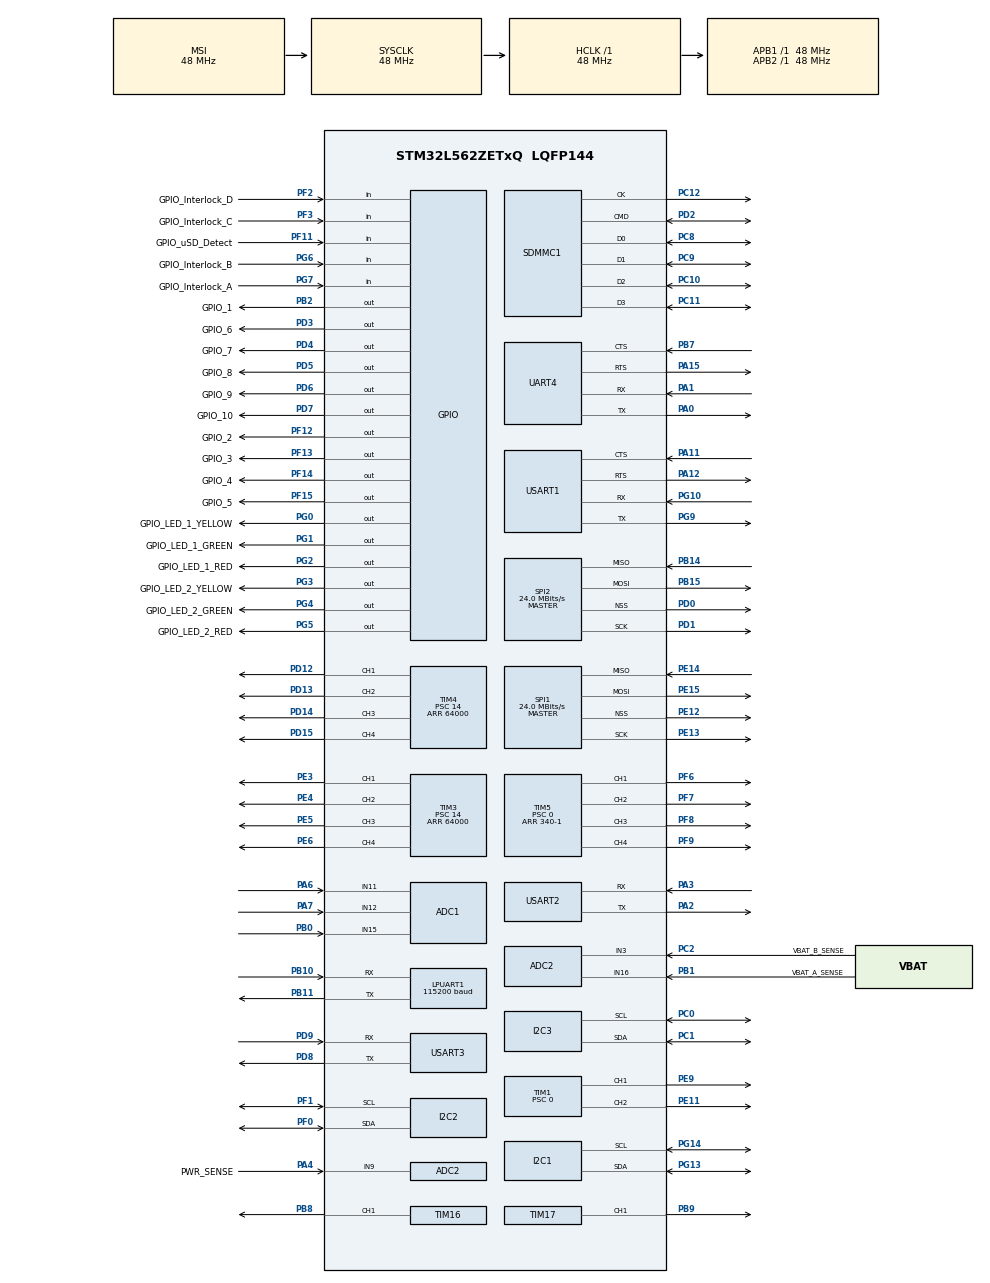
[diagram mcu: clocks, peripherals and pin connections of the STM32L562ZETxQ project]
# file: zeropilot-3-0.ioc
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ADC1.Channel-0\#ChannelRegularConversion=ADC_CHANNEL_11
ADC1.Channel-3\#ChannelRegularConversion=ADC_CHANNEL_12
ADC1.Channel-4\#ChannelRegularConversion=ADC_CHANNEL_15
ADC1.ClockPrescaler=ADC_CLOCK_ASYNC_DIV256
ADC1.ContinuousConvMode=ENABLE
ADC1.DMAContinuousRequests=ENABLE
ADC1.NbrOfConversion=3
ADC1.NbrOfConversionFlag=1
ADC1.OffsetNumber-3\#ChannelRegularConversion=ADC_OFFSET_NONE
ADC1.OffsetNumber-4\#ChannelRegularConversion=ADC_OFFSET_NONE
ADC1.Rank-3\#ChannelRegularConversion=2
ADC1.Rank-4\#ChannelRegularConversion=3
ADC1.SamplingTime-0\#ChannelRegularConversion=ADC_SAMPLETIME_640CYCLES_5
ADC1.SamplingTime-3\#ChannelRegularConversion=ADC_SAMPLETIME_640CYCLES_5
ADC1.SamplingTime-4\#ChannelRegularConversion=ADC_SAMPLETIME_640CYCLES_5
ADC1.master=1
ADC2.AutoInjectedConv-ADC_Injected_ConversionMode=ENABLE
ADC2.Channel-0\#ChannelRegularConversion=ADC_CHANNEL_3
ADC2.Channel-3\#ChannelRegularConversion=ADC_CHANNEL_9
ADC2.Channel-4\#ChannelRegularConversion=ADC_CHANNEL_16
ADC2.ClockPrescaler=ADC_CLOCK_ASYNC_DIV256
ADC2.ContinuousConvMode=ENABLE
ADC2.DMAContinuousRequests=ENABLE
ADC2.NbrOfConversion=3
ADC2.NbrOfConversionFlag=1
ADC2.OffsetNumber-3\#ChannelRegularConversion=ADC_OFFSET_NONE
ADC2.OffsetNumber-4\#ChannelRegularConversion=ADC_OFFSET_NONE
ADC2.Rank-3\#ChannelRegularConversion=2
ADC2.Rank-4\#ChannelRegularConversion=3
ADC2.SamplingTime-0\#ChannelRegularConversion=ADC_SAMPLETIME_640CYCLES_5
ADC2.SamplingTime-3\#ChannelRegularConversion=ADC_SAMPLETIME_640CYCLES_5
ADC2.SamplingTime-4\#ChannelRegularConversion=ADC_SAMPLETIME_640CYCLES_5
Dma.ADC1.8.Channel_PRIV_NPRIV=DMA_CHANNEL_NPRIV_DISABLE
Dma.ADC1.8.Direction=DMA_PERIPH_TO_MEMORY
Dma.ADC1.8.EventEnable=DISABLE
Dma.ADC1.8.Instance=DMA2_Channel1
Dma.ADC1.8.MemDataAlignment=DMA_MDATAALIGN_WORD
Dma.ADC1.8.MemInc=DMA_MINC_ENABLE
Dma.ADC1.8.Mode=DMA_CIRCULAR
Dma.ADC1.8.PeriphDataAlignment=DMA_PDATAALIGN_HALFWORD
Dma.ADC1.8.PeriphInc=DMA_PINC_DISABLE
Dma.ADC1.8.Polarity=HAL_DMAMUX_REQ_GEN_RISING
Dma.ADC1.8.Priority=DMA_PRIORITY_LOW
Dma.ADC1.8.RequestNumber=1
Dma.ADC1.8.SignalID=NONE
Dma.ADC1.8.SyncEnable=DISABLE
Dma.ADC1.8.SyncPolarity=HAL_DMAMUX_SYNC_NO_EVENT
Dma.ADC1.8.SyncRequestNumber=1
Dma.ADC1.8.SyncSignalID=NONE
Dma.ADC2.9.Channel_PRIV_NPRIV=DMA_CHANNEL_NPRIV_DISABLE
Dma.ADC2.9.Direction=DMA_PERIPH_TO_MEMORY
Dma.ADC2.9.EventEnable=DISABLE
Dma.ADC2.9.Instance=DMA2_Channel2
Dma.ADC2.9.MemDataAlignment=DMA_MDATAALIGN_WORD
Dma.ADC2.9.MemInc=DMA_MINC_ENABLE
Dma.ADC2.9.Mode=DMA_CIRCULAR
Dma.ADC2.9.PeriphDataAlignment=DMA_PDATAALIGN_HALFWORD
Dma.ADC2.9.PeriphInc=DMA_PINC_DISABLE
Dma.ADC2.9.Polarity=HAL_DMAMUX_REQ_GEN_RISING
Dma.ADC2.9.Priority=DMA_PRIORITY_LOW
Dma.ADC2.9.RequestNumber=1
Dma.ADC2.9.SignalID=NONE
Dma.ADC2.9.SyncEnable=DISABLE
Dma.ADC2.9.SyncPolarity=HAL_DMAMUX_SYNC_NO_EVENT
Dma.ADC2.9.SyncRequestNumber=1
Dma.ADC2.9.SyncSignalID=NONE
Dma.Request0=TIM16_CH1
Dma.Request1=TIM17_CH1
Dma.Request2=TIM1_CH1
Dma.Request3=TIM1_CH2
Dma.Request4=TIM5_CH1
Dma.Request5=TIM5_CH2
Dma.Request6=TIM5_CH3
Dma.Request7=TIM5_CH4
Dma.Request8=ADC1
Dma.Request9=ADC2
Dma.TIM16_CH1.0.Channel_PRIV_NPRIV=DMA_CHANNEL_NPRIV_DISABLE
Dma.TIM16_CH1.0.Direction=DMA_MEMORY_TO_PERIPH
Dma.TIM16_CH1.0.EventEnable=DISABLE
Dma.TIM16_CH1.0.Instance=DMA1_Channel1
Dma.TIM16_CH1.0.MemDataAlignment=DMA_MDATAALIGN_WORD
Dma.TIM16_CH1.0.MemInc=DMA_MINC_ENABLE
Dma.TIM16_CH1.0.Mode=DMA_CIRCULAR
Dma.TIM16_CH1.0.PeriphDataAlignment=DMA_PDATAALIGN_WORD
Dma.TIM16_CH1.0.PeriphInc=DMA_PINC_DISABLE
Dma.TIM16_CH1.0.Polarity=HAL_DMAMUX_REQ_GEN_RISING
Dma.TIM16_CH1.0.Priority=DMA_PRIORITY_HIGH
Dma.TIM16_CH1.0.RequestNumber=1
Dma.TIM16_CH1.0.SignalID=NONE
Dma.TIM16_CH1.0.SyncEnable=DISABLE
Dma.TIM16_CH1.0.SyncPolarity=HAL_DMAMUX_SYNC_NO_EVENT
Dma.TIM16_CH1.0.SyncRequestNumber=1
Dma.TIM16_CH1.0.SyncSignalID=NONE
Dma.TIM17_CH1.1.Channel_PRIV_NPRIV=DMA_CHANNEL_NPRIV_DISABLE
Dma.TIM17_CH1.1.Direction=DMA_MEMORY_TO_PERIPH
Dma.TIM17_CH1.1.EventEnable=DISABLE
Dma.TIM17_CH1.1.Instance=DMA1_Channel2
Dma.TIM17_CH1.1.MemDataAlignment=DMA_MDATAALIGN_WORD
Dma.TIM17_CH1.1.MemInc=DMA_MINC_ENABLE
Dma.TIM17_CH1.1.Mode=DMA_CIRCULAR
Dma.TIM17_CH1.1.PeriphDataAlignment=DMA_PDATAALIGN_WORD
Dma.TIM17_CH1.1.PeriphInc=DMA_PINC_DISABLE
Dma.TIM17_CH1.1.Polarity=HAL_DMAMUX_REQ_GEN_RISING
Dma.TIM17_CH1.1.Priority=DMA_PRIORITY_HIGH
Dma.TIM17_CH1.1.RequestNumber=1
Dma.TIM17_CH1.1.SignalID=NONE
Dma.TIM17_CH1.1.SyncEnable=DISABLE
Dma.TIM17_CH1.1.SyncPolarity=HAL_DMAMUX_SYNC_NO_EVENT
Dma.TIM17_CH1.1.SyncRequestNumber=1
Dma.TIM17_CH1.1.SyncSignalID=NONE
Dma.TIM1_CH1.2.Channel_PRIV_NPRIV=DMA_CHANNEL_NPRIV_DISABLE
Dma.TIM1_CH1.2.Direction=DMA_MEMORY_TO_PERIPH
Dma.TIM1_CH1.2.EventEnable=DISABLE
Dma.TIM1_CH1.2.Instance=DMA1_Channel3
Dma.TIM1_CH1.2.MemDataAlignment=DMA_MDATAALIGN_WORD
Dma.TIM1_CH1.2.MemInc=DMA_MINC_ENABLE
Dma.TIM1_CH1.2.Mode=DMA_CIRCULAR
Dma.TIM1_CH1.2.PeriphDataAlignment=DMA_PDATAALIGN_WORD
Dma.TIM1_CH1.2.PeriphInc=DMA_PINC_DISABLE
Dma.TIM1_CH1.2.Polarity=HAL_DMAMUX_REQ_GEN_RISING
Dma.TIM1_CH1.2.Priority=DMA_PRIORITY_HIGH
Dma.TIM1_CH1.2.RequestNumber=1
Dma.TIM1_CH1.2.SignalID=NONE
Dma.TIM1_CH1.2.SyncEnable=DISABLE
Dma.TIM1_CH1.2.SyncPolarity=HAL_DMAMUX_SYNC_NO_EVENT
Dma.TIM1_CH1.2.SyncRequestNumber=1
Dma.TIM1_CH1.2.SyncSignalID=NONE
Dma.TIM1_CH2.3.Channel_PRIV_NPRIV=DMA_CHANNEL_NPRIV_DISABLE
Dma.TIM1_CH2.3.Direction=DMA_MEMORY_TO_PERIPH
Dma.TIM1_CH2.3.EventEnable=DISABLE
Dma.TIM1_CH2.3.Instance=DMA1_Channel4
Dma.TIM1_CH2.3.MemDataAlignment=DMA_MDATAALIGN_WORD
Dma.TIM1_CH2.3.MemInc=DMA_MINC_ENABLE
Dma.TIM1_CH2.3.Mode=DMA_CIRCULAR
Dma.TIM1_CH2.3.PeriphDataAlignment=DMA_PDATAALIGN_WORD
Dma.TIM1_CH2.3.PeriphInc=DMA_PINC_DISABLE
Dma.TIM1_CH2.3.Polarity=HAL_DMAMUX_REQ_GEN_RISING
Dma.TIM1_CH2.3.Priority=DMA_PRIORITY_HIGH
Dma.TIM1_CH2.3.RequestNumber=1
Dma.TIM1_CH2.3.SignalID=NONE
Dma.TIM1_CH2.3.SyncEnable=DISABLE
Dma.TIM1_CH2.3.SyncPolarity=HAL_DMAMUX_SYNC_NO_EVENT
Dma.TIM1_CH2.3.SyncRequestNumber=1
Dma.TIM1_CH2.3.SyncSignalID=NONE
Dma.TIM5_CH1.4.Channel_PRIV_NPRIV=DMA_CHANNEL_NPRIV_DISABLE
Dma.TIM5_CH1.4.Direction=DMA_MEMORY_TO_PERIPH
Dma.TIM5_CH1.4.EventEnable=DISABLE
Dma.TIM5_CH1.4.Instance=DMA1_Channel5
Dma.TIM5_CH1.4.MemDataAlignment=DMA_MDATAALIGN_WORD
Dma.TIM5_CH1.4.MemInc=DMA_MINC_ENABLE
Dma.TIM5_CH1.4.Mode=DMA_CIRCULAR
Dma.TIM5_CH1.4.PeriphDataAlignment=DMA_PDATAALIGN_WORD
Dma.TIM5_CH1.4.PeriphInc=DMA_PINC_DISABLE
Dma.TIM5_CH1.4.Polarity=HAL_DMAMUX_REQ_GEN_RISING
Dma.TIM5_CH1.4.Priority=DMA_PRIORITY_HIGH
Dma.TIM5_CH1.4.RequestNumber=1
Dma.TIM5_CH1.4.SignalID=NONE
Dma.TIM5_CH1.4.SyncEnable=DISABLE
Dma.TIM5_CH1.4.SyncPolarity=HAL_DMAMUX_SYNC_NO_EVENT
Dma.TIM5_CH1.4.SyncRequestNumber=1
Dma.TIM5_CH1.4.SyncSignalID=NONE
Dma.TIM5_CH2.5.Channel_PRIV_NPRIV=DMA_CHANNEL_NPRIV_DISABLE
Dma.TIM5_CH2.5.Direction=DMA_MEMORY_TO_PERIPH
Dma.TIM5_CH2.5.EventEnable=DISABLE
Dma.TIM5_CH2.5.Instance=DMA1_Channel6
Dma.TIM5_CH2.5.MemDataAlignment=DMA_MDATAALIGN_WORD
Dma.TIM5_CH2.5.MemInc=DMA_MINC_ENABLE
Dma.TIM5_CH2.5.Mode=DMA_CIRCULAR
Dma.TIM5_CH2.5.PeriphDataAlignment=DMA_PDATAALIGN_WORD
Dma.TIM5_CH2.5.PeriphInc=DMA_PINC_DISABLE
Dma.TIM5_CH2.5.Polarity=HAL_DMAMUX_REQ_GEN_RISING
Dma.TIM5_CH2.5.Priority=DMA_PRIORITY_HIGH
Dma.TIM5_CH2.5.RequestNumber=1
Dma.TIM5_CH2.5.SignalID=NONE
Dma.TIM5_CH2.5.SyncEnable=DISABLE
Dma.TIM5_CH2.5.SyncPolarity=HAL_DMAMUX_SYNC_NO_EVENT
Dma.TIM5_CH2.5.SyncRequestNumber=1
Dma.TIM5_CH2.5.SyncSignalID=NONE
Dma.TIM5_CH3.6.Channel_PRIV_NPRIV=DMA_CHANNEL_NPRIV_DISABLE
Dma.TIM5_CH3.6.Direction=DMA_MEMORY_TO_PERIPH
Dma.TIM5_CH3.6.EventEnable=DISABLE
Dma.TIM5_CH3.6.Instance=DMA1_Channel7
Dma.TIM5_CH3.6.MemDataAlignment=DMA_MDATAALIGN_WORD
Dma.TIM5_CH3.6.MemInc=DMA_MINC_ENABLE
Dma.TIM5_CH3.6.Mode=DMA_CIRCULAR
Dma.TIM5_CH3.6.PeriphDataAlignment=DMA_PDATAALIGN_WORD
Dma.TIM5_CH3.6.PeriphInc=DMA_PINC_DISABLE
Dma.TIM5_CH3.6.Polarity=HAL_DMAMUX_REQ_GEN_RISING
Dma.TIM5_CH3.6.Priority=DMA_PRIORITY_HIGH
Dma.TIM5_CH3.6.RequestNumber=1
Dma.TIM5_CH3.6.SignalID=NONE
Dma.TIM5_CH3.6.SyncEnable=DISABLE
Dma.TIM5_CH3.6.SyncPolarity=HAL_DMAMUX_SYNC_NO_EVENT
Dma.TIM5_CH3.6.SyncRequestNumber=1
Dma.TIM5_CH3.6.SyncSignalID=NONE
Dma.TIM5_CH4.7.Channel_PRIV_NPRIV=DMA_CHANNEL_NPRIV_DISABLE
Dma.TIM5_CH4.7.Direction=DMA_MEMORY_TO_PERIPH
Dma.TIM5_CH4.7.EventEnable=DISABLE
Dma.TIM5_CH4.7.Instance=DMA1_Channel8
Dma.TIM5_CH4.7.MemDataAlignment=DMA_MDATAALIGN_WORD
Dma.TIM5_CH4.7.MemInc=DMA_MINC_ENABLE
Dma.TIM5_CH4.7.Mode=DMA_CIRCULAR
Dma.TIM5_CH4.7.PeriphDataAlignment=DMA_PDATAALIGN_WORD
Dma.TIM5_CH4.7.PeriphInc=DMA_PINC_DISABLE
Dma.TIM5_CH4.7.Polarity=HAL_DMAMUX_REQ_GEN_RISING
Dma.TIM5_CH4.7.Priority=DMA_PRIORITY_HIGH
Dma.TIM5_CH4.7.RequestNumber=1
Dma.TIM5_CH4.7.SignalID=NONE
Dma.TIM5_CH4.7.SyncEnable=DISABLE
Dma.TIM5_CH4.7.SyncPolarity=HAL_DMAMUX_SYNC_NO_EVENT
Dma.TIM5_CH4.7.SyncRequestNumber=1
Dma.TIM5_CH4.7.SyncSignalID=NONE
FREERTOS.Tasks01=defaultTask,24,128,StartDefaultTask,Default,NULL,Dynamic,NULL,NULL
I2C1.Timing=0x20303E5D
I2C2.Timing=0x20303E5D
I2C3.Timing=0x20303E5D
LPUART1.BaudRate=115200
Mcu.Family=STM32L5
Mcu.Name=STM32L562ZETxQ
Mcu.Package=LQFP144
NVIC.DMA1_Channel1_IRQn=true\:5\:0\:false\:false\:true\:true\:false\:true\:true
NVIC.DMA1_Channel2_IRQn=true\:5\:0\:false\:false\:true\:true\:false\:true\:true
NVIC.DMA1_Channel3_IRQn=true\:5\:0\:false\:false\:true\:true\:false\:true\:true
NVIC.DMA1_Channel4_IRQn=true\:5\:0\:false\:false\:true\:true\:false\:true\:true
NVIC.DMA1_Channel5_IRQn=true\:5\:0\:false\:false\:true\:true\:false\:true\:true
NVIC.DMA1_Channel6_IRQn=true\:5\:0\:false\:false\:true\:true\:false\:true\:true
NVIC.DMA1_Channel7_IRQn=true\:5\:0\:false\:false\:true\:true\:false\:true\:true
NVIC.DMA1_Channel8_IRQn=true\:5\:0\:false\:false\:true\:true\:false\:true\:true
NVIC.DMA2_Channel1_IRQn=true\:5\:0\:false\:false\:true\:true\:false\:true\:true
NVIC.DMA2_Channel2_IRQn=true\:5\:0\:false\:false\:true\:true\:false\:true\:true
NVIC.PriorityGroup=NVIC_PRIORITYGROUP_3
NVIC.TIM6_IRQn=true\:7\:0\:false\:false\:true\:false\:false\:true\:true
NVIC.TimeBase=TIM6_IRQn
NVIC.TimeBaseIP=TIM6
PA0.Mode=Asynchronous
PA0.Signal=UART4_TX
PA1.Mode=Asynchronous
PA1.Signal=UART4_RX
PA11.Mode=CTS_RTS
PA11.Signal=USART1_CTS
PA12.Mode=CTS_RTS
PA12.Signal=USART1_RTS
PA15\ (JTDI).Mode=CTS_RTS
PA15\ (JTDI).Signal=UART4_RTS
PA2.Mode=Asynchronous
PA2.Signal=USART2_TX
PA3.Mode=Asynchronous
PA3.Signal=USART2_RX
PA4.GPIO_Label=PWR_SENSE
PA4.GPIO_Mode=GPIO_MODE_ANALOG
PA4.GPIO_PuPd=GPIO_NOPULL
PA4.Signal=ADCx_IN9
PA6.Signal=ADCx_IN11
PA7.Signal=ADCx_IN12
PB0.Signal=ADCx_IN15
PB1.GPIO_Label=VBAT_A_SENSE
PB1.GPIO_Mode=GPIO_MODE_ANALOG
PB1.GPIO_PuPd=GPIO_NOPULL
PB1.Signal=ADCx_IN16
PB10.Mode=Asynchronous
PB10.Signal=LPUART1_RX
PB11.Mode=Asynchronous
PB11.Signal=LPUART1_TX
PB14.Mode=Full_Duplex_Master
PB14.PinAttribute=Free
PB14.Signal=SPI2_MISO
PB15.Mode=Full_Duplex_Master
PB15.PinAttribute=Free
PB15.Signal=SPI2_MOSI
PB2.GPIO_Label=GPIO_1
PB2.Signal=GPIO_Output
PB7.Mode=CTS_RTS
PB7.Signal=UART4_CTS
PB8.Signal=S_TIM16_CH1
PB9.Signal=S_TIM17_CH1
PC0.Mode=I2C
PC0.Signal=I2C3_SCL
PC1.Mode=I2C
PC1.Signal=I2C3_SDA
PC10.Mode=SD_4_bits_Wide_bus
PC10.Signal=SDMMC1_D2
PC11.Mode=SD_4_bits_Wide_bus
PC11.Signal=SDMMC1_D3
PC12.Mode=SD_4_bits_Wide_bus
PC12.Signal=SDMMC1_CK
PC2.GPIO_Label=VBAT_B_SENSE
PC2.GPIO_Mode=GPIO_MODE_ANALOG
PC2.GPIO_PuPd=GPIO_NOPULL
PC2.Signal=ADCx_IN3
PC8.Mode=SD_4_bits_Wide_bus
PC8.Signal=SDMMC1_D0
PC9.Mode=SD_4_bits_Wide_bus
PC9.Signal=SDMMC1_D1
PD0.Mode=NSS_Signal_Hard_Output
PD0.PinAttribute=Free
PD0.Signal=SPI2_NSS
PD1.Mode=Full_Duplex_Master
PD1.PinAttribute=Free
PD1.Signal=SPI2_SCK
PD12.Signal=S_TIM4_CH1
PD13.Signal=S_TIM4_CH2
PD14.Signal=S_TIM4_CH3
PD15.PinAttribute=Free
PD15.Signal=S_TIM4_CH4
PD2.Mode=SD_4_bits_Wide_bus
PD2.Signal=SDMMC1_CMD
PD3.GPIO_Label=GPIO_6
PD3.Signal=GPIO_Output
PD4.GPIO_Label=GPIO_7
PD4.Signal=GPIO_Output
PD5.GPIO_Label=GPIO_8
PD5.Signal=GPIO_Output
PD6.GPIO_Label=GPIO_9
PD6.Signal=GPIO_Output
PD7.GPIO_Label=GPIO_10
PD7.Signal=GPIO_Output
PD8.Mode=Asynchronous
PD8.PinAttribute=Free
PD8.Signal=USART3_TX
PD9.Mode=Asynchronous
PD9.PinAttribute=Free
PD9.Signal=USART3_RX
PE11.PinAttribute=Free
PE11.Signal=S_TIM1_CH2
PE12.Mode=NSS_Signal_Hard_Output
PE12.Signal=SPI1_NSS
PE13.Mode=Full_Duplex_Master
PE13.Signal=SPI1_SCK
PE14.Mode=Full_Duplex_Master
PE14.Signal=SPI1_MISO
PE15.Mode=Full_Duplex_Master
PE15.Signal=SPI1_MOSI
PE3.Signal=S_TIM3_CH1
PE4.Signal=S_TIM3_CH2
PE5.Signal=S_TIM3_CH3
PE6.Signal=S_TIM3_CH4
PE9.Signal=S_TIM1_CH1
PF0.Mode=I2C
PF0.Signal=I2C2_SDA
PF1.Mode=I2C
PF1.Signal=I2C2_SCL
PF11.GPIO_Label=GPIO_uSD_Detect
PF11.Signal=GPIO_Input
PF12.GPIO_Label=GPIO_2
PF12.Signal=GPIO_Output
PF13.GPIO_Label=GPIO_3
PF13.Signal=GPIO_Output
PF14.GPIO_Label=GPIO_4
PF14.Signal=GPIO_Output
PF15.GPIO_Label=GPIO_5
PF15.Signal=GPIO_Output
PF2.GPIO_Label=GPIO_Interlock_D
PF2.Signal=GPIO_Input
PF3.GPIO_Label=GPIO_Interlock_C
PF3.Signal=GPIO_Input
PF6.Signal=S_TIM5_CH1
PF7.Signal=S_TIM5_CH2
PF8.Signal=S_TIM5_CH3
PF9.Signal=S_TIM5_CH4
PG0.GPIO_Label=GPIO_LED_1_YELLOW
PG0.GPIO_ModeDefaultOutputPP=GPIO_MODE_OUTPUT_PP
PG0.GPIO_PuPd=GPIO_NOPULL
PG0.PinState=GPIO_PIN_SET
PG0.Signal=GPIO_Output
PG1.GPIO_Label=GPIO_LED_1_GREEN
PG1.PinState=GPIO_PIN_SET
PG1.Signal=GPIO_Output
PG10.Mode=Asynchronous
PG10.Signal=USART1_RX
PG13.Mode=I2C
PG13.Signal=I2C1_SDA
PG14.Mode=I2C
PG14.Signal=I2C1_SCL
PG2.GPIO_Label=GPIO_LED_1_RED
PG2.PinAttribute=Free
PG2.PinState=GPIO_PIN_SET
PG2.Signal=GPIO_Output
PG3.GPIO_Label=GPIO_LED_2_YELLOW
PG3.PinAttribute=Free
PG3.PinState=GPIO_PIN_SET
PG3.Signal=GPIO_Output
PG4.GPIO_Label=GPIO_LED_2_GREEN
PG4.PinAttribute=Free
PG4.PinState=GPIO_PIN_SET
PG4.Signal=GPIO_Output
PG5.GPIO_Label=GPIO_LED_2_RED
PG5.PinState=GPIO_PIN_SET
PG5.Signal=GPIO_Output
PG6.GPIO_Label=GPIO_Interlock_B
PG6.Signal=GPIO_Input
PG7.GPIO_Label=GPIO_Interlock_A
PG7.Signal=GPIO_Input
PG9.Mode=Asynchronous
PG9.Signal=USART1_TX
ProjectManager.HeapSize=0x400
ProjectManager.StackSize=0x800
ProjectManager.TargetToolchain=STM32CubeIDE
RCC.ADCFreq_Value=8000000
RCC.AHBFreq_Value=48000000
RCC.APB1Freq_Value=48000000
RCC.APB1TimFreq_Value=48000000
RCC.APB2Freq_Value=48000000
RCC.APB2TimFreq_Value=48000000
RCC.CortexFreq_Value=48000000
RCC.HCLKFreq_Value=48000000
RCC.HSE_VALUE=8000000
RCC.HSI48_VALUE=48000000
RCC.HSI_VALUE=16000000
RCC.LSE_VALUE=32768
RCC.MSIClockRange=RCC_MSIRANGE_11
RCC.MSI_VALUE=48000000
RCC.PLLN=17
RCC.PLLP=RCC_PLLP_DIV17
RCC.PLLSAI1M=2
RCC.PLLSAI1R=RCC_PLLR_DIV8
RCC.PLLSAI1Source=RCC_PLLSAI1SOURCE_HSI
RCC.PLLSAI2Source=RCC_PLLSAI2SOURCE_HSI
RCC.PLLSourceVirtual=RCC_PLLSOURCE_HSI
RCC.SYSCLKFreq_VALUE=48000000
RCC.USBFreq_Value=32000000
RCC.VCOOutputFreq_Value=272000000
SDMMC1.ClockDiv=0
SDMMC1.HardwareFlowControl=SDMMC_HARDWARE_FLOW_CONTROL_DISABLE
SH.ADCx_IN11.0=ADC1_IN11,IN11-Single-Ended
SH.ADCx_IN12.0=ADC1_IN12,IN12-Single-Ended
SH.ADCx_IN15.0=ADC1_IN15,IN15-Single-Ended
SH.ADCx_IN16.0=ADC2_IN16,IN16-Single-Ended
SH.ADCx_IN3.0=ADC2_IN3,IN3-Single-Ended
SH.ADCx_IN9.0=ADC2_IN9,IN9-Single-Ended
SH.S_TIM16_CH1.0=TIM16_CH1,PWM Generation1 CH1
SH.S_TIM17_CH1.0=TIM17_CH1,PWM Generation1 CH1
SH.S_TIM1_CH1.0=TIM1_CH1,PWM Generation1 CH1
SH.S_TIM1_CH2.0=TIM1_CH2,PWM Generation2 CH2
SH.S_TIM3_CH1.0=TIM3_CH1,PWM Generation1 CH1
SH.S_TIM3_CH2.0=TIM3_CH2,PWM Generation2 CH2
SH.S_TIM3_CH3.0=TIM3_CH3,PWM Generation3 CH3
SH.S_TIM3_CH4.0=TIM3_CH4,PWM Generation4 CH4
SH.S_TIM4_CH1.0=TIM4_CH1,PWM Generation1 CH1
SH.S_TIM4_CH2.0=TIM4_CH2,PWM Generation2 CH2
SH.S_TIM4_CH3.0=TIM4_CH3,PWM Generation3 CH3
SH.S_TIM4_CH4.0=TIM4_CH4,PWM Generation4 CH4
SH.S_TIM5_CH1.0=TIM5_CH1,PWM Generation1 CH1
SH.S_TIM5_CH2.0=TIM5_CH2,PWM Generation2 CH2
SH.S_TIM5_CH3.0=TIM5_CH3,PWM Generation3 CH3
SH.S_TIM5_CH4.0=TIM5_CH4,PWM Generation4 CH4
SPI1.BaudRatePrescaler=SPI_BAUDRATEPRESCALER_2
SPI1.CalculateBaudRate=24.0 MBits/s
SPI1.Direction=SPI_DIRECTION_2LINES
SPI1.Mode=SPI_MODE_MASTER
SPI1.VirtualNSS=VM_NSSHARD
SPI1.VirtualType=VM_MASTER
SPI2.BaudRatePrescaler=SPI_BAUDRATEPRESCALER_2
SPI2.CalculateBaudRate=24.0 MBits/s
SPI2.DataSize=SPI_DATASIZE_8BIT
SPI2.Direction=SPI_DIRECTION_2LINES
SPI2.Mode=SPI_MODE_MASTER
SPI2.VirtualNSS=VM_NSSHARD
SPI2.VirtualType=VM_MASTER
TIM1.Channel-PWM\ Generation1\ CH1=TIM_CHANNEL_1
TIM1.Channel-PWM\ Generation2\ CH2=TIM_CHANNEL_2
TIM1.Period=320-1
TIM1.Prescaler=0
TIM16.Channel=TIM_CHANNEL_1
TIM16.Period=340-1
TIM16.Prescaler=0
TIM17.Channel=TIM_CHANNEL_1
TIM17.Period=340-1
TIM17.Prescaler=0
TIM3.AutoReloadPreload=TIM_AUTORELOAD_PRELOAD_DISABLE
TIM3.Channel-PWM\ Generation1\ CH1=TIM_CHANNEL_1
TIM3.Channel-PWM\ Generation2\ CH2=TIM_CHANNEL_2
TIM3.Channel-PWM\ Generation3\ CH3=TIM_CHANNEL_3
TIM3.Channel-PWM\ Generation4\ CH4=TIM_CHANNEL_4
TIM3.Period=64000
TIM3.Prescaler=14
TIM4.Channel-PWM\ Generation1\ CH1=TIM_CHANNEL_1
TIM4.Channel-PWM\ Generation2\ CH2=TIM_CHANNEL_2
TIM4.Channel-PWM\ Generation3\ CH3=TIM_CHANNEL_3
TIM4.Channel-PWM\ Generation4\ CH4=TIM_CHANNEL_4
TIM4.Period=64000
TIM4.Prescaler=14
TIM5.Channel-PWM\ Generation1\ CH1=TIM_CHANNEL_1
TIM5.Channel-PWM\ Generation2\ CH2=TIM_CHANNEL_2
TIM5.Channel-PWM\ Generation3\ CH3=TIM_CHANNEL_3
TIM5.Channel-PWM\ Generation4\ CH4=TIM_CHANNEL_4
TIM5.Period=340-1
TIM5.Prescaler=0
USART1.VirtualMode-Asynchronous=VM_ASYNC
USART2.VirtualMode-Asynchronous=VM_ASYNC
USART3.VirtualMode-Asynchronous=VM_ASYNC
VP_FATFS_VS_SDIO.Mode=SDIO
VP_FREERTOS_VS_CMSIS_V2.Mode=CMSIS_V2
VP_ICACHE_VS_ICACHE.Mode=DefaultMode
VP_SYS_VS_tim6.Mode=TIM6
VP_TIM16_VS_ClockSourceINT.Mode=Enable_Timer
VP_TIM17_VS_ClockSourceINT.Mode=Enable_Timer
board=custom

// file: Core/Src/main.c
/* USER CODE BEGIN Header */
/**
 ******************************************************************************
 * @file           : main.c
 * @brief          : Main program body
 ******************************************************************************
 * @attention
 *
 * Copyright (c) 2023 STMicroelectronics.
 * All rights reserved.
 *
 * This software is licensed under terms that can be found in the LICENSE file
 * in the root directory of this software component.
 * If no LICENSE file comes with this software, it is provided AS-IS.
 *
 ******************************************************************************
 */
/* USER CODE END Header */
#include "main.h"

#include "adc.h"
#include "app_fatfs.h"
#include "cmsis_os.h"
#include "dma.h"
#include "gpio.h"
#include "i2c.h"
#include "icache.h"
#include "sdmmc.h"
#include "spi.h"
#include "tim.h"
#include "usart.h"

void SystemClock_Config(void);
void MX_FREERTOS_Init(void);

/* USER CODE BEGIN 0 */
void losInit(void) {
    /* MCU Configuration--------------------------------------------------------*/

    /* Reset of all peripherals, Initializes the Flash interface and the Systick. */
    HAL_Init();

    /* Configure the system clock */
    SystemClock_Config();

    /* Initialize all configured peripherals */
    MX_GPIO_Init();
    MX_DMA_Init();
    MX_I2C1_Init();
    MX_I2C2_Init();
    MX_I2C3_Init();
    MX_LPUART1_UART_Init();
    MX_UART4_Init();
    MX_USART1_UART_Init();
    MX_USART2_UART_Init();
    MX_USART3_UART_Init();
    MX_SPI1_Init();
    MX_SPI2_Init();
    MX_TIM3_Init();
    MX_TIM4_Init();
    MX_TIM5_Init();
    MX_TIM16_Init();
    MX_TIM17_Init();
    MX_ADC1_Init();
    MX_ADC2_Init();
    MX_SDMMC1_SD_Init();
    MX_TIM1_Init();
    // There is a question of if the ICACHE should be enabled. It improves performance but there is
    // suggestion that it could make the system non-deterministic
    MX_ICACHE_Init();
    if (MX_FATFS_Init() != APP_OK) {
        Error_Handler();
    }

    /* Init scheduler */
    osKernelInitialize(); /* Call init function for freertos objects (in freertos.c) */
    MX_FREERTOS_Init();
}
void losKernelStart(void) {
    /* Start scheduler */
    osKernelStart();
}
/* USER CODE END 0 */

void SystemClock_Config(void) {
    RCC_OscInitTypeDef RCC_OscInitStruct = {0};
    RCC_ClkInitTypeDef RCC_ClkInitStruct = {0};

    /** Configure the main internal regulator output voltage
     */
    if (HAL_PWREx_ControlVoltageScaling(PWR_REGULATOR_VOLTAGE_SCALE1) != HAL_OK) {
        Error_Handler();
    }

    /** Initializes the RCC Oscillators according to the specified parameters
     * in the RCC_OscInitTypeDef structure.
     */
    RCC_OscInitStruct.OscillatorType = RCC_OSCILLATORTYPE_HSI | RCC_OSCILLATORTYPE_MSI;
    RCC_OscInitStruct.HSIState = RCC_HSI_ON;
    RCC_OscInitStruct.HSICalibrationValue = RCC_HSICALIBRATION_DEFAULT;
    RCC_OscInitStruct.MSIState = RCC_MSI_ON;
    RCC_OscInitStruct.MSICalibrationValue = RCC_MSICALIBRATION_DEFAULT;
    RCC_OscInitStruct.MSIClockRange = RCC_MSIRANGE_11;
    RCC_OscInitStruct.PLL.PLLState = RCC_PLL_ON;
    RCC_OscInitStruct.PLL.PLLSource = RCC_PLLSOURCE_HSI;
    RCC_OscInitStruct.PLL.PLLM = 1;
    RCC_OscInitStruct.PLL.PLLN = 17;
    RCC_OscInitStruct.PLL.PLLP = RCC_PLLP_DIV17;
    RCC_OscInitStruct.PLL.PLLQ = RCC_PLLQ_DIV2;
    RCC_OscInitStruct.PLL.PLLR = RCC_PLLR_DIV2;
    if (HAL_RCC_OscConfig(&RCC_OscInitStruct) != HAL_OK) {
        Error_Handler();
    }

    /** Initializes the CPU, AHB and APB buses clocks
     */
    RCC_ClkInitStruct.ClockType =
        RCC_CLOCKTYPE_HCLK | RCC_CLOCKTYPE_SYSCLK | RCC_CLOCKTYPE_PCLK1 | RCC_CLOCKTYPE_PCLK2;
    RCC_ClkInitStruct.SYSCLKSource = RCC_SYSCLKSOURCE_MSI;
    RCC_ClkInitStruct.AHBCLKDivider = RCC_SYSCLK_DIV1;
    RCC_ClkInitStruct.APB1CLKDivider = RCC_HCLK_DIV1;
    RCC_ClkInitStruct.APB2CLKDivider = RCC_HCLK_DIV1;

    if (HAL_RCC_ClockConfig(&RCC_ClkInitStruct, FLASH_LATENCY_2) != HAL_OK) {
        Error_Handler();
    }
}

void HAL_TIM_PeriodElapsedCallback(TIM_HandleTypeDef *htim) {
    if (htim->Instance == TIM6) {
        HAL_IncTick();
    }
}

void Error_Handler(void) {
    /* USER CODE BEGIN Error_Handler_Debug */
    /* User can add his own implementation to report the HAL error return state */
    __disable_irq();
    HAL_GPIO_WritePin(GPIO_LED_1_RED_GPIO_Port, GPIO_LED_1_RED_Pin, GPIO_PIN_RESET);
    HAL_GPIO_WritePin(GPIO_LED_1_GREEN_GPIO_Port, GPIO_LED_1_GREEN_Pin, GPIO_PIN_SET);
    HAL_GPIO_WritePin(GPIO_LED_1_YELLOW_GPIO_Port, GPIO_LED_1_YELLOW_Pin, GPIO_PIN_SET);
    HAL_GPIO_WritePin(GPIO_LED_2_RED_GPIO_Port, GPIO_LED_2_RED_Pin, GPIO_PIN_SET);
    HAL_GPIO_WritePin(GPIO_LED_2_GREEN_GPIO_Port, GPIO_LED_2_GREEN_Pin, GPIO_PIN_SET);
    HAL_GPIO_WritePin(GPIO_LED_2_YELLOW_GPIO_Port, GPIO_LED_2_YELLOW_Pin, GPIO_PIN_SET);
    while (1) {
    }
    /* USER CODE END Error_Handler_Debug */
}
